AUTOSAR XML (schema 4-2-1)
standard types defined: UInt32, UInt8
package /MICROSAR/VEC_SecurityAccessFord_swc
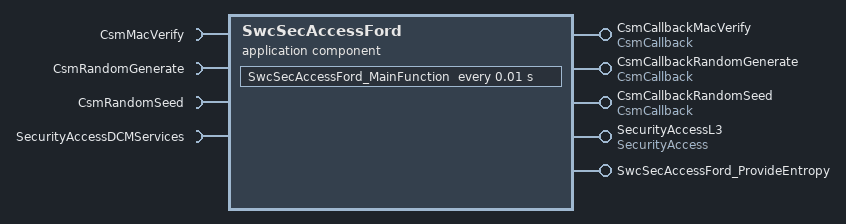
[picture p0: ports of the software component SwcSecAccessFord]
  application sw component type SwcSecAccessFord
    5 x provide port:
      CsmCallbackMacVerify: server-com-spec{operation=JobFinished, queue-length=1}, provided-interface=CsmCallback
      CsmCallbackRandomGenerate: server-com-spec{operation=JobFinished, queue-length=1}, provided-interface=CsmCallback
      CsmCallbackRandomSeed: server-com-spec{operation=JobFinished, queue-length=1}, provided-interface=CsmCallback
      SecurityAccessL3: provided-com-specs=[{operation=CompareKey, queue-length=1}, {operation=GetSeed, queue-length=1}], provided-interface=SecurityAccess
      SwcSecAccessFord_ProvideEntropy: server-com-spec{operation=ProvideEntropy, queue-length=1}, provided-interface=SwcSecAccessFord_ProvideEntropy
    4 x require port:
      CsmMacVerify: required-interface=CsmMacVerify
      CsmRandomGenerate: required-interface=CsmRandomGenerate
      CsmRandomSeed: required-interface=CsmRandomSeed
      SecurityAccessDCMServices: required-interface=SecurityAccessDCMServices
    behavior SwcSecAccessFord_InternalBehavior
      5 x operation invoked event:
        OIT_VEC_SecurityAccessFord_CallbackNotificationMacVerify_CsmCallbackMacVerify_JobFinished: start-on-event=SwcSecAccessFord_CallbackNotificationMacVerify, operation=CsmCallbackMacVerify.JobFinished
        OIT_VEC_SecurityAccessFord_CallbackNotificationRandomGenerate_CsmCallbackRandomGenerate_JobFinished: start-on-event=SwcSecAccessFord_CallbackNotificationRandomGenerate, operation=CsmCallbackRandomGenerate.JobFinished
        OIT_VEC_SecurityAccessFord_CallbackNotification_CsmCallback_JobFinished: start-on-event=SwcSecAccessFord_CallbackNotificationRandomSeed, operation=CsmCallbackRandomSeed.JobFinished
        OIT_VEC_SecurityAccessFord_CompareKey_L1_SecurityAccess_CompareKey: start-on-event=SwcSecAccessFord_CompareKey_L3, operation=SecurityAccessL3.CompareKey
        OIT_VEC_SecurityAccessFord_GetSeed_L1_SecurityAccess_GetSeed: start-on-event=SwcSecAccessFord_GetSeed_L3, operation=SecurityAccessL3.GetSeed
      init event VEC_SecurityAccessFord_InitEvent: start-on-event=SwcSecAccessFord_Init
      timing event TMT_VEC_SecurityAccessFord_MainFunction: start-on-event=SwcSecAccessFord_MainFunction, period=0.01
      operation invoked event OIT_SwcSecAccessFord_ProvideEntropy_SwcSecAccessFord_ProvideEntropy_ProvideEntropy: start-on-event=SwcSecAccessFord_ProvideEntropy, operation=SwcSecAccessFord_ProvideEntropy.ProvideEntropy
      8 x runnable:
        SwcSecAccessFord_CallbackNotificationMacVerify
        SwcSecAccessFord_CallbackNotificationRandomGenerate
        SwcSecAccessFord_CallbackNotificationRandomSeed
        SwcSecAccessFord_CompareKey_L3
          5 x sync call, all with timeout=0:
            AC_CsmMacVerify_MacVerifyFinish: operation=CsmMacVerify.MacVerifyFinish
            AC_CsmMacVerify_MacVerifyStart: operation=CsmMacVerify.MacVerifyStart
            AC_CsmMacVerify_MacVerifyUpdate: operation=CsmMacVerify.MacVerifyUpdate
            SC_SecurityAccessDCMServices_GetSecurityLevel: operation=SecurityAccessDCMServices.GetSecurityLevel
            SC_SecurityAccessDCMServices_GetSecurityLevelFixedBytes: operation=SecurityAccessDCMServices.GetSecurityLevelFixedBytes
        SwcSecAccessFord_GetSeed_L3
          sync call AC_CsmRandomGenerate_RandomGenerate: operation=CsmRandomGenerate.RandomGenerate, timeout=0
        SwcSecAccessFord_Init
        SwcSecAccessFord_MainFunction
          sync call SC_CsmRandomSeed_RandomSeedFinish: operation=CsmRandomSeed.RandomSeedFinish, timeout=0
          sync call SC_CsmRandomSeed_RandomSeedStart: operation=CsmRandomSeed.RandomSeedStart, timeout=0
          sync call SC_CsmRandomSeed_RandomSeedUpdate: operation=CsmRandomSeed.RandomSeedUpdate, timeout=0
        SwcSecAccessFord_ProvideEntropy
  swc implementation SwcSecAccessFord_Implementation: behavior=SwcSecAccessFord_InternalBehavior
    code-descriptors:
      code Default: artifact-descriptors=autosar-engineering-object={short-label=Default, category=SWSRC}
package /MICROSAR/VEC_SecurityAccessFord_swc/DataTypes
  13 x impl type:
    Csm_ReturnType: category=VALUE, base-type=Csm_ReturnType, compu {0=CSM_E_OK, 1=CSM_E_NOT_OK, 2=CSM_E_BUSY, 3=CSM_E_SMALL_BUFFER, 4=CSM_E_ENTROPY_EXHAUSTION}  # The data type Csm_ReturnType indicates the result of a service request.
    Csm_VerifyResultType: category=VALUE, base-type=Csm_VerifyResultType, compu {0=CSM_E_VER_OK, 1=CSM_E_VER_NOT_OK}  # The data type Csm_VerifyResultType indicates the result of a verification operation (used by services MacVerify and SignatureVerify).
    Dcm_Data12ByteType: category=ARRAY, sw-calibration-access=READ-ONLY
      element Dcm_Data12ByteTypeElement: array-size=12, array-size-semantics=FIXED-SIZE, implementation-data-type=uint8
    Dcm_Data16ByteType: category=ARRAY, sw-calibration-access=READ-ONLY
      element Dcm_Data100ByteTypeElement: array-size=16, array-size-semantics=FIXED-SIZE, implementation-data-type=UInt8
    Dcm_NegativeResponseCodeType:
      category=VALUE
      base-type=Dcm_NegativeResponseCodeType
      compu {0=DCM_E_POSITIVERESPONSE, 16=DCM_E_GENERALREJECT, 17=DCM_E_SERVICENOTSUPPORTED, 18=DCM_E_SUBFUNCTIONNOTSUPPORTED, 19=DCM_E_INCORRECTMESSAGELENGTHORINVALIDFORMAT, 20=DCM_E_RESPONSETOOLONG, 33=DCM_E_BUSYREPEATREQUEST, 34=DCM_E_CONDITIONSNOTCORRECT, 36=DCM_E_REQUESTSEQUENCEERROR, 37=DCM_E_NORESPONSEFROMSUBNETCOMPONENT, 38=DCM_E_FAILUREPREVENTSEXECUTIONOFREQUESTEDACTION, 49=DCM_E_REQUESTOUTOFRANGE, 51=DCM_E_SECURITYACCESSDENIED, 53=DCM_E_INVALIDKEY, 54=DCM_E_EXCEEDNUMBEROFATTEMPTS, 55=DCM_E_REQUIREDTIMEDELAYNOTEXPIRED, 112=DCM_E_UPLOADDOWNLOADNOTACCEPTED, 113=DCM_E_TRANSFERDATASUSPENDED, 114=DCM_E_GENERALPROGRAMMINGFAILURE, 115=DCM_E_WRONGBLOCKSEQUENCECOUNTER, 120=DCM_E_REQUESTCORRECTLYRECEIVEDRESPONSEPENDING, 126=DCM_E_SUBFUNCTIONNOTSUPPORTEDINACTIVESESSION, 127=DCM_E_SERVICENOTSUPPORTEDINACTIVESESSION, 129=DCM_E_RPMTOOHIGH, 130=DCM_E_RPMTOOLOW, 131=DCM_E_ENGINEISRUNNING, 132=DCM_E_ENGINEISNOTRUNNING, 133=DCM_E_ENGINERUNTIMETOOLOW, 134=DCM_E_TEMPERATURETOOHIGH, 135=DCM_E_TEMPERATURETOOLOW, 136=DCM_E_VEHICLESPEEDTOOHIGH, 137=DCM_E_VEHICLESPEEDTOOLOW, 138=DCM_E_THROTTLE_PEDALTOOHIGH, 139=DCM_E_THROTTLE_PEDALTOOLOW, 140=DCM_E_TRANSMISSIONRANGENOTINNEUTRAL, 141=DCM_E_TRANSMISSIONRANGENOTINGEAR, 143=DCM_E_BRAKESWITCH_NOTCLOSED, 144=DCM_E_SHIFTERLEVERNOTINPARK, 145=DCM_E_TORQUECONVERTERCLUTCHLOCKED, 146=DCM_E_VOLTAGETOOHIGH, 147=DCM_E_VOLTAGETOOLOW}
    Dcm_OpStatusType: category=VALUE, base-type=Dcm_OpStatusType, compu {0=DCM_INITIAL, 1=DCM_PENDING, 2=DCM_CANCEL, 3=DCM_FORCE_RCRRP_OK, 64=DCM_FORCE_RCRRP_NOT_OK}
    Dcm_ProtocolType: compu {0=DCM_OBD_ON_CAN, 1=DCM_OBD_ON_FLEXRAY, 2=DCM_OBD_ON_IP, 3=DCM_UDS_ON_CAN, 4=DCM_UDS_ON_FLEXRAY, 5=DCM_UDS_ON_IP, 12=DCM_NO_ACTIVE_PROTOCOL, 240..254=DCM_SUPPLIER_1..DCM_SUPPLIER_15}, implementation-data-type=uint8
    Dcm_SecLevelType: compu {0=DCM_SEC_LEV_LOCKED, 1=DCM_SEC_LEV_L1, 2=DCM_SEC_LEV_L2}, implementation-data-type=uint8
    Dcm_SesCtrlType: compu {1=DCM_DEFAULT_SESSION, 2=DCM_PROGRAMMING_SESSION, 3=DCM_EXTENDED_DIAGNOSTIC_SESSION}, implementation-data-type=uint8
    MacVerifyDataBuffer: category=ARRAY, sw-calibration-access=READ-ONLY  # Used as Buffer for service.
      element MacVerifyDataBufferElement: array-size=128, array-size-semantics=FIXED-SIZE, implementation-data-type=UInt8
    RandomGenerateResultBuffer: category=ARRAY, sw-calibration-access=READ-ONLY  # Used as Buffer for service.
      element RandomGenerateResultBufferElement: array-size=128, array-size-semantics=FIXED-SIZE, implementation-data-type=UInt8
    RandomSeedDataBuffer: category=ARRAY, sw-calibration-access=READ-ONLY  # Used as Buffer for service.
      element RandomSeedDataBufferElement: array-size=128, array-size-semantics=FIXED-SIZE, implementation-data-type=UInt8
    SymKeyType: category=STRUCTURE, dynamic-array-size-profile=None  # This type is used for Csm key parameters of type SymKey
      element length: implementation-data-type=UInt32
      element data: category=ARRAY
        element SymKeyDataElement: array-size=20, array-size-semantics=FIXED-SIZE, implementation-data-type=UInt8
package /MICROSAR/VEC_SecurityAccessFord_swc/DataTypes/BaseTypes
  4 x base type, all with category=FIXED_LENGTH, base-type-size=8, base-type-encoding=NONE, native-declaration=uint8:
    Csm_ReturnType
    Csm_VerifyResultType
    Dcm_NegativeResponseCodeType
    Dcm_OpStatusType
package /MICROSAR/VEC_SecurityAccessFord_swc/DataTypes/DataConstr
  range UInt32_Constr: raw 0
  range UInt8_Constr: raw 0
package /MICROSAR/VEC_SecurityAccessFord_swc/Interfaces
  6 x client server interface, all with is-service=true:
    CsmCallback
      operation JobFinished: possible-error=CsmCallback/CSM_E_NOT_OK
        arg retVal: type=Csm_ReturnType, direction=IN, server-argument-impl-policy=USE-ARGUMENT-TYPE
      error CSM_E_NOT_OK: error-code=1  # Request failed.
    CsmMacVerify  # A message authentication code (MAC) is a short piece of information used to authenticate a message. A MAC algorithm accepts as input a secret key and an arbitrary-length message to be authenticated, and outputs a MAC. The MAC value protects both a message's data integrity as well as its authenticity, by allowing verifiers (who also possess the secret key) to detect any changes to the message content.
      operation MacVerifyFinish: possible-error=[CsmMacVerify/CSM_E_NOT_OK, CsmMacVerify/CSM_E_BUSY, CsmMacVerify/CSM_E_SMALL_BUFFER]  # This interface shall be used to finish the MAC verification service.
        arg MacBuffer: type=MacVerifyDataBuffer, direction=IN, server-argument-impl-policy=USE-ARGUMENT-TYPE
        arg MacLength: type=UInt32, direction=IN, server-argument-impl-policy=USE-ARGUMENT-TYPE
        arg resultBuffer: type=Csm_VerifyResultType, direction=OUT, server-argument-impl-policy=USE-ARGUMENT-TYPE
      operation MacVerifyStart: possible-error=[CsmMacVerify/CSM_E_NOT_OK, CsmMacVerify/CSM_E_BUSY]  # This interface shall be used to initialize the MAC verification service of the CSM module.
        arg key: type=SymKeyType, direction=IN, server-argument-impl-policy=USE-ARGUMENT-TYPE
      operation MacVerifyUpdate: possible-error=[CsmMacVerify/CSM_E_NOT_OK, CsmMacVerify/CSM_E_BUSY]  # This interface shall be used to feed the MAC verification service with the input data.
        arg dataBuffer: type=MacVerifyDataBuffer, direction=IN, server-argument-impl-policy=USE-ARGUMENT-TYPE
        arg dataLength: type=UInt32, direction=IN, server-argument-impl-policy=USE-ARGUMENT-TYPE
      error CSM_E_BUSY: error-code=2  # The service request failed because the service is still busy.
      error CSM_E_NOT_OK: error-code=1  # The execution of the called function failed.
      error CSM_E_SMALL_BUFFER: error-code=3  # The service request failed because the provided buffer is too small to store the result of the service.
    CsmRandomGenerate  # The generation of a random number is based on the seed, which was previously set with the interfaces Csm_RandomSeedStart, Csm_RandomSeedUpdate, and Csm_RandomSeedFinish. These interfaces follow the streaming approach. Thus it is possible to feed the seed e.g. from different sources. To generate a random number, no streaming approach is necessary. The interface Csm_RandomGenerate can be called arbitrarily often to generate multiple random numbers.
      operation RandomGenerate: possible-error=[CsmRandomGenerate/CSM_E_NOT_OK, CsmRandomGenerate/CSM_E_BUSY, CSM_E_ENTROPY_EXHAUSTION]  # This interface shall be used to start the random number generation service of the CSM module.
        arg resultBuffer: type=RandomGenerateResultBuffer, direction=OUT, server-argument-impl-policy=USE-ARGUMENT-TYPE
        arg resultLength: type=UInt32, direction=IN, server-argument-impl-policy=USE-ARGUMENT-TYPE
      error CSM_E_BUSY: error-code=2  # The service request failed because the service is still busy.
      error CSM_E_ENTROPY_EXHAUSTION: error-code=4  # The service request failed because the entropy of the random number generator is exhausted
      error CSM_E_NOT_OK: error-code=1  # The execution of the called function failed.
    CsmRandomSeed  # The random interface provides generation of random numbers. A random number can be generated either by a physical device (true random number generator), or by computational algorithms (pseudo random number generator). The randomness of pseudo random number generators can be increased by an appropriate selection of the seed.
      operation RandomSeedFinish: possible-error=[CsmRandomSeed/CSM_E_NOT_OK, CsmRandomSeed/CSM_E_BUSY, CsmRandomSeed/CSM_E_SMALL_BUFFER]  # This interface shall be used to finish the random seed service.
      operation RandomSeedStart: possible-error=[CsmRandomSeed/CSM_E_NOT_OK, CsmRandomSeed/CSM_E_BUSY]  # This interface shall be used to initialize the random seed service of the CSM module.
      operation RandomSeedUpdate: possible-error=[CsmRandomSeed/CSM_E_NOT_OK, CsmRandomSeed/CSM_E_BUSY]  # This interface shall be used to feed the random seed service with the input data.
        arg seedBuffer: type=RandomSeedDataBuffer, direction=IN, server-argument-impl-policy=USE-ARGUMENT-TYPE
        arg seedLength: type=UInt32, direction=IN, server-argument-impl-policy=USE-ARGUMENT-TYPE
      error CSM_E_BUSY: error-code=2  # The service request failed because the service is still busy.
      error CSM_E_NOT_OK: error-code=1  # The execution of the called function failed.
      error CSM_E_SMALL_BUFFER: error-code=3  # The service request failed because the provided buffer is too small to store the result of the service.
    SecurityAccess
      operation CompareKey: possible-error=[SecurityAccess/E_NOT_OK, DCM_E_PENDING, DCM_E_COMPARE_KEY_FAILED]
        arg Key: type=Dcm_Data16ByteType, direction=IN, server-argument-impl-policy=USE-ARGUMENT-TYPE
        arg OpStatus: type=Dcm_OpStatusType, direction=IN, server-argument-impl-policy=USE-ARGUMENT-TYPE
        arg ErrorCode: type=Dcm_NegativeResponseCodeType, direction=OUT, server-argument-impl-policy=USE-ARGUMENT-TYPE
      operation GetSeed: possible-error=[SecurityAccess/E_NOT_OK, DCM_E_PENDING]
        arg OpStatus: type=Dcm_OpStatusType, direction=IN, server-argument-impl-policy=USE-ARGUMENT-TYPE
        arg Seed: type=Dcm_Data16ByteType, direction=OUT, server-argument-impl-policy=USE-ARGUMENT-TYPE
        arg ErrorCode: type=Dcm_NegativeResponseCodeType, direction=OUT, server-argument-impl-policy=USE-ARGUMENT-TYPE
      error DCM_E_COMPARE_KEY_FAILED: error-code=11
      error DCM_E_PENDING: error-code=10
      error E_NOT_OK: error-code=1
    SecurityAccessDCMServices
      5 x operation:
        GetActiveProtocol: possible-error=SecurityAccessDCMServices/E_NOT_OK
          arg ActiveProtocol: type=Dcm_ProtocolType, direction=OUT, server-argument-impl-policy=USE-ARGUMENT-TYPE
        GetSecurityLevel: possible-error=SecurityAccessDCMServices/E_NOT_OK
          arg SecLevel: type=Dcm_SecLevelType, direction=OUT, server-argument-impl-policy=USE-ARGUMENT-TYPE
        GetSecurityLevelFixedBytes: possible-error=[SecurityAccessDCMServices/E_NOT_OK, DCM_E_BUFFERTOOLOW]
          arg SecLevel: type=Dcm_SecLevelType, direction=IN, server-argument-impl-policy=USE-ARGUMENT-TYPE
          arg FixedBytes: type=Dcm_Data12ByteType, direction=OUT, server-argument-impl-policy=USE-ARGUMENT-TYPE
          arg BufferSize: type=uint8, direction=INOUT, server-argument-impl-policy=USE-ARGUMENT-TYPE
        GetSesCtrlType: possible-error=SecurityAccessDCMServices/E_NOT_OK
          arg SesCtrlType: type=Dcm_SesCtrlType, direction=OUT, server-argument-impl-policy=USE-ARGUMENT-TYPE
        ResetToDefaultSession: possible-error=SecurityAccessDCMServices/E_NOT_OK
      error DCM_E_BUFFERTOOLOW: error-code=42
      error E_NOT_OK: error-code=1
package /MICROSAR/VEC_SecurityAccessFord_swc/PortInterfaces
  client server interface SwcSecAccessFord_ProvideEntropy
    operation ProvideEntropy: possible-error=[SwcSecAccessFord_ProvideEntropy/E_NOT_OK, E_BUSY]
      arg seedPtr: type=RandomSeedDataBuffer, direction=IN, server-argument-impl-policy=USE-ARGUMENT-TYPE
      arg seedLength: type=UInt32, direction=IN, server-argument-impl-policy=USE-ARGUMENT-TYPE
    error E_BUSY: error-code=2
    error E_NOT_OK: error-code=1
